# RK3399-AP register map
File version: 1
CPU: CA7 r0p1, little endian, MPU, FPU, I-cache, D-cache, VTOR, 4 interrupt priority bits, 0 interrupts
Registers are 32-bit, read-write, reset 0x0 unless marked. A register's access mark holds for its fields unless they carry their own. Offsets are from the block's base; [hi:lo] are bit positions.

## GMAC (part 2 of 2)
Base 0xFE300000
0x190 GMAC_MMC_RXMCFRMCNT_G — MMC RX Multicast Frame Good Counter/MMC RX Mulitcast Frame Good Counter
  [31:0] RXMULTICASTFRAMES_G — Number of good multicast frames received.
0x194 GMAC_MMC_RXCRCERR — MMC RX Carrier
  [31:0] RXCRCERROR — Number of frames received with CRC error.
0x1C8 GMAC_MMC_RXLENERR — MMC RX Length Error
  [31:0] RXLENGTHERROR — Number of frames received with length error (Length type field ≠frame size), for all frames with valid length field.
0x1D4 GMAC_MMC_RXFIFOOVRFLW — MMC RX FIFO Overflow
  [31:0] RXFIFOOVERFLOW — Number of missed received frames due to FIFO overflow.
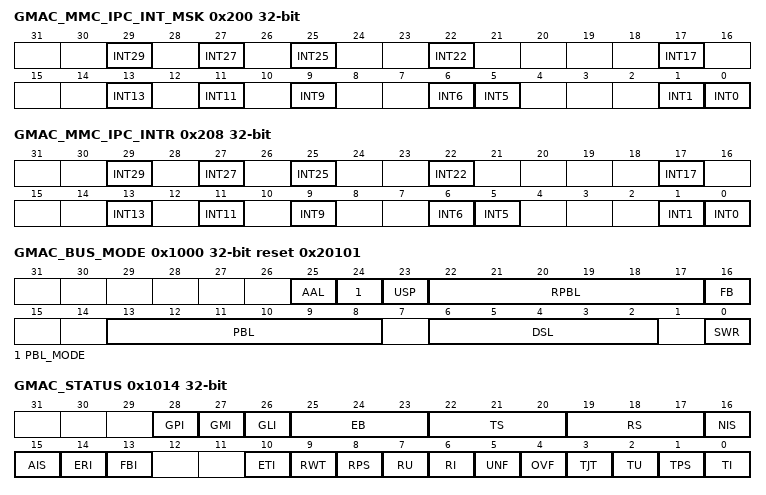
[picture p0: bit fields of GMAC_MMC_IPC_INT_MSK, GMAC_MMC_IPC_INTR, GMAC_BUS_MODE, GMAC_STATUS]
0x200 GMAC_MMC_IPC_INT_MSK — MMC Receive Checksum Offload Interrupt Mask Register
  [29] INT29 — Setting this bit masks the interrupt when the rxicmp_err_octets counter reaches half the maximum value, and also when it reaches the maximum value.
  [27] INT27 — Setting this bit masks the interrupt when the rxtcp_err_octets counter reaches half the maximum value, and also when it reaches the maximum value.
  [25] INT25 — Setting this bit masks the interrupt when the rxudp_err_octets counter reaches half the maximum value, and also when it reaches the maximum value.
  [22] INT22 — Setting this bit masks the interrupt when the rxipv6_hdrerr_octets counter reaches half the maximum value, and also when it reaches the maximum value.
  [17] INT17 — Setting this bit masks the interrupt when the rxipv4_hdrerr_octets counter reaches half the maximum value, and also when it reaches the maximum value.
  [13] INT13 — Setting this bit masks the interrupt when the rxicmp_err_frms counter reaches half the maximum value, and also when it reaches the maximum value.
  [11] INT11 — Setting this bit masks the interrupt when the rxtcp_err_frms counter reaches half the maximum value, and also when it reaches the maximum value.
  [9] INT9 — Setting this bit masks the interrupt when the rxudp_err_frms counter reaches half the maximum value, and also when it reaches the maximum value.
  [6] INT6 — Setting this bit masks the interrupt when the rxipv6_hdrerr_frms counter reaches half the maximum value, and also when it reaches the maximum value.
  [5] INT5 — Setting this bit masks the interrupt when the rxipv6_gd_frms counter reaches half the maximum value, and also when it reaches the maximum value.
  [1] INT1 — Setting this bit masks the interrupt when the rxipv4_hdrerr_frms counter reaches half the maximum value, and also when it reaches the maximum value.
  [0] INT0 — Setting this bit masks the interrupt when the rxipv4_gd_frms counter reaches half the maximum value, and also when it reaches the maximum value.
0x208 GMAC_MMC_IPC_INTR ro — MMC Receive Checksum Offload Interrupt Register
  [29] INT29 read-clears — The bit is set when the rxicmp_err_octets counter reaches half the maximum value, and also when it reaches the maximum value.
  [27] INT27 read-clears — The bit is set when the rxtcp_err_octets counter reaches half the maximum value, and also when it reaches the maximum value.
  [25] INT25 read-clears — The bit is set when the rxudp_err_octets counter reaches half the maximum value, and also when it reaches the maximum value.
  [22] INT22 read-clears — The bit is set when the rxipv6_hdrerr_octets counter reaches half the maximum value, and also when it reaches the maximum value.
  [17] INT17 read-clears — The bit is set when the rxipv4_hdrerr_octets counter reaches half the maximum value, and also when it reaches the maximum value.
  [13] INT13 read-clears — The bit is set when the rxicmp_err_frms counter reaches half the maximum value, and also when it reaches the maximum value.
  [11] INT11 read-clears — The bit is set when the rxtcp_err_frms counter reaches half the maximum value, and also when it reaches the maximum value.
  [9] INT9 read-clears — The bit is set when the rxudp_err_frms counter reaches half the maximum value, and also when it reaches the maximum value.
  [6] INT6 read-clears — The bit is set when the rxipv6_hdrerr_frms counter reaches half the maximum value, and also when it reaches the maximum value.
  [5] INT5 read-clears — The bit is set when the rxipv6_gd_frms counter reaches half the maximum value, and also when it reaches the maximum value.
  [1] INT1 read-clears — The bit is set when the rxipv4_hdrerr_frms counter reaches half the maximum value, and also when it reaches the maximum value.
  [0] INT0 read-clears — The bit is set when the rxipv4_gd_frms counter reaches half the maximum value, and also when it reaches the maximum value.
0x210 GMAC_MMC_RXIPV4GFRM — MMC RX IPV4 Good Frame
  [31:0] RXIPV4_GD_FRMS — Number of good IPv4 datagrams received with the TCP, UDP, or ICMP payload
0x214 GMAC_MMC_RXIPV4HDERRFRM — MMC RX IPV4 Head Error Frame
  [31:0] RXIPV4_HDRERR_FRMS — Number of IPv4 datagrams received with header (checksum, length, or version mismatch) errors
0x224 GMAC_MMC_RXIPV6GFRM — MMC RX IPV6 Good Frame
  [31:0] RXIPV6_GD_FRMS — Number of good IPv6 datagrams received with TCP, UDP, or ICMP payloads.
0x228 GMAC_MMC_RXIPV6HDERRFRM — MMC RX IPV6 Head Error Frame
  [31:0] RXIPV6_HDRERR_FRMS — Number of IPv6 datagrams received with header errors (length or version mismatch).
0x234 GMAC_MMC_RXUDPERRFRM — MMC RX UDP Error Frame
  [31:0] RXUDP_ERR_FRMS — Number of good IP datagrams whose UDP payload has a checksum error.
0x23C GMAC_MMC_RXTCPERRFRM — MMC RX TCP Error Frame
  [31:0] RXTCP_ERR_FRMS — Number of good IP datagrams whose TCP payload has a checksum error.
0x244 GMAC_MMC_RXICMPERRFRM — MMC RX ICMP Error Frame
  [31:0] RXICMP_ERR_FRMS — Number of good IP datagrams whose ICMP payload has a checksum error.
0x254 GMAC_MMC_RXIPV4HDERROCT — MMC RX OCTET IPV4 Head Error
  [31:0] RXIPV4_HDRERR_OCTETS — Number of bytes received in IPv4 datagrams with header errors (checksum, length, version mismatch). The value in the Length field of IPv4 header is used to update this counter.
0x268 GMAC_MMC_RXIPV6HDERROCT — MMC RX OCTET IPV6 Head Error
  [31:0] RXIPV6_HDRERR_OCTETS — Number of bytes received in IPv6 datagrams with header errors (length, version mismatch). The value in the IPv6 header\'s Length field is used to update this counter.
0x274 GMAC_MMC_RXUDPERROCT — MMC RX OCTET UDP Error
  [31:0] RXUDP_ERR_OCTETS — Number of bytes received in a UDP segment that had checksum errors.
0x27C GMAC_MMC_RXTCPERROCT — MMC RX OCTET TCP Error
  [31:0] RXTCP_ERR_OCTETS — Number of bytes received in a TCP segment with checksum errors.
0x284 GMAC_MMC_RXICMPERROCT — MMC RX OCTET ICMP Error
  [31:0] RXICMP_ERR_OCTETS — Number of bytes received in an ICMP segment with checksum errors.
0x1000 GMAC_BUS_MODE access per field reset 0x20101 — Bus Mode Register
  [25] AAL rw — Address-Aligned Beats When this bit is set high and the FB bit equals 1, the AXI interface generates all bursts aligned to the start address LS bits. If the FB bit equals 0, the first burst (accessing the data buffer\'s start address) is not aligned, but subsequent bursts are aligned to the address.
  [24] PBL_MODE rw — 8xPBL Mode When set high, this bit multiplies the PBL value programmed (bits [22:17] and bits [13:8]) eight times. Thus the DMA will transfer data in to a maximum of 8, 16, 32, 64, 128, and 256 beats depending on the PBL value.
  [23] USP rw — Use Separate PBL When set high, it configures the RxDMA to use the value configured in bits [22:17] as PBL while the PBL value in bits [13:8] is applicable to TxDMA operations only. When reset to low, the PBL value in bits [13:8] is applicable for both DMA engines.
  [22:17] RPBL rw — RxDMA PBL These bits indicate the maximum number of beats to be transferred in one RxDMA transaction. This will be the maximum value that is used in a single block Read/Write. The RxDMA will always attempt to burst as specified in RPBL each time it starts a Burst transfer on the host bus. RPBL can be programmed with permissible values of 1, 2, 4, 8, 16, and 32. Any other value will result in undefined behavior. These bits are valid and applicable only when USP is set high.
  [16] FB rw — Fixed Burst This bit controls whether the AXI Master interface performs fixed burst transfers or not. When set, the AHB will use only SINGLE, INCR4, INCR8 or INCR16 during start of normal burst transfers. When reset, the AXI will use SINGLE and INCR burst transfer operations.
  [13:8] PBL rw — Programmable Burst Length These bits indicate the maximum number of beats to be transferred in one DMA transaction. This will be the maximum value that is used in a single block Read/Write. The DMA will always attempt to burst as specified in PBL each time it starts a Burst transfer on the host bus. PBL can be programmed with permissible values of 1, 2, 4, 8, 16, and 32. Any other value will result in undefined behavior. When USP is set high, this PBL value is applicable for TxDMA transactions only. The PBL values have the following limitations. The maximum number of beats (PBL) possible is limited by the size of the Tx FIFO and Rx FIFO in the MTL layer and the data bus width on the DMA. The FIFO has a constraint that the maximum beat supported is half the depth of the FIFO, except when specified (as given below). For different data bus widths and FIFO sizes, the valid PBL range (including x8 mode) is provided in the following table. If the PBL is common for both transmit and receive DMA, the minimum Rx FIFO and Tx FIFO depths must be considered. Do not program out-of-range PBL values, because the system may not behave properly. For TxFIFO, valid PBL range in full duplex mode and duplex mode is 128 or less. For RxFIFO, valid PBL range in full duplex mode is all.
  [6:2] DSL rw — Descriptor Skip Length This bit specifies the number of dword to skip between two unchained descriptors. The address skipping starts from the end of current descriptor to the start of next descriptor. When DSL value equals zero, then the descriptor table is taken as contiguous by the DMA, in Ring mode.
  [0] SWR wo write-clears — Software Reset When this bit is set, the MAC DMA Controller resets all GMAC Subsystem internal registers and logic. It is cleared automatically after the reset operation has completed in all of the core clock domains. Read a 0 value in this bit before re-programming any register of the core. Note: The reset operation is completed only when all the resets in all the active clock domains are de-asserted. Hence it is essential that all the PHY inputs clocks (applicable for the selected PHY interface) are present for software reset completion.
0x1004 GMAC_TX_POLL_DEMAND ro — Transmit Poll Demand Register
  [31:0] TPD — Transmit Poll Demand When these bits are written with any value, the DMA reads the current descriptor pointed to by Register GMAC_CUR_HOST_TX_DESC. If that descriptor is not available (owned by Host), transmission returns to the Suspend state and DMA Register GMAC_STATUS[2] is asserted. If the descriptor is available, transmission resumes.
0x1008 GMAC_RX_POLL_DEMAND ro — Receive Poll Demand Register
  [31:0] RPD — Receive Poll Demand When these bits are written with any value, the DMA reads the current descriptor pointed to by Register GMAC_CUR_HOST_RX_DESC. If that descriptor is not available (owned by Host), reception returns to the Suspended state and Register GMAC_STATUS[7] is not asserted. If the descriptor is available, the Receive DMA returns to active state.
0x100C GMAC_RX_DESC_LIST_ADDR — Receive Descriptor List Address Register
  [31:0] SRL — Start of Receive List This field contains the base address of the First Descriptor in the Receive Descriptor list. The LSB bits [1/2/3:0] for 32/64/128-bit bus width) will be ignored and taken as all-zero by the DMA internally. Hence these LSB bits are Read Only.
0x1010 GMAC_TX_DESC_LIST_ADDR — Transmit Descriptor List Address Register
  [31:0] STL — Start of Transmit List This field contains the base address of the First Descriptor in the Transmit Descriptor list. The LSB bits [1/2/3:0] for 32/64/128-bit bus width) will be ignored and taken as all-zero by the DMA internally. Hence these LSB bits are Read Only.
0x1014 GMAC_STATUS access per field — Status Register
  [28] GPI ro — GMAC PMT Interrupt This bit indicates an interrupt event in the GMAC core\'s PMT module. The software must read the corresponding registers in the GMAC core to get the exact cause of interrupt and clear its source to reset this bit to 1\'b0. The interrupt signal from the GMAC subsystem (sbd_intr_o) is high when this bit is high.
  [27] GMI ro — GMAC MMC Interrupt This bit reflects an interrupt event in the MMC module of the GMAC core. The software must read the corresponding registers in the GMAC core to get the exact cause of interrupt and clear the source of interrupt to make this bit as 1\'b0. The interrupt signal from the GMAC subsystem (sbd_intr_o) is high when this bit is high.
  [26] GLI ro — GMAC Line interface Interrupt This bit reflects an interrupt event in the GMAC Core\'s PCS or RGMII interface block. The software must read the corresponding registers in the GMAC core to get the exact cause of interrupt and clear the source of interrupt to make this bit as 1\'b0. The interrupt signal from the GMAC subsystem (sbd_intr_o) is high when this bit is high.
  [25:23] EB ro — Error Bits These bits indicate the type of error that caused a Bus Error (e.g., error response on the AXI interface). Valid only with Fatal Bus Error bit (Register GMAC_STATUS[13]) set. This field does not generate an interrupt. Bit 23: 1\'b1 Error during data transfer by TxDMA 1\'b0 Error during data transfer by RxDMA Bit 24: 1\'b1 Error during read transfer 1\'b0 Error during write transfer Bit 25: 1\'b1 Error during descriptor access 1\'b0 Error during data buffer access
  [22:20] TS ro — Transmit Process State These bits indicate the Transmit DMA FSM state. This field does not generate an interrupt. 3\'b000: Stopped; Reset or Stop Transmit Command issued. 3\'b001: Running; Fetching Transmit Transfer Descriptor. 3\'b010: Running; Waiting for status. 3\'b011: Running; Reading Data from host memory buffer and queuing it to transmit buffer (Tx FIFO). 3\'b100: TIME_STAMP write state. 3\'b101: Reserved for future use. 3\'b110: Suspended; Transmit Descriptor Unavailable or Transmit Buffer Underflow. 3\'b111: Running; Closing Transmit Descriptor.
  [19:17] RS ro — Receive Process State These bits indicate the Receive DMA FSM state. This field does not generate an interrupt. 3\'b000: Stopped: Reset or Stop Receive Command issued. 3\'b001: Running: Fetching Receive Transfer Descriptor. 3\'b010: Reserved for future use. 3\'b011: Running: Waiting for receive packet. 3\'b100: Suspended: Receive Descriptor Unavailable. 3\'b101: Running: Closing Receive Descriptor. 3\'b110: TIME_STAMP write state. 3\'b111: Running: Transferring the receive packet data from receive buffer to host memory.
  [16] NIS rw write-1-clears — Normal Interrupt Summary Normal Interrupt Summary bit value is the logical OR of the following when the corresponding interrupt bits are enabled in Register OP_MODE: Register GMAC_STATUS[0]: Transmit Interrupt Register GMAC_STATUS[2]: Transmit Buffer Unavailable Register GMAC_STATUS[6]: Receive Interrupt Register GMAC_STATUS[14]: Early Receive Interrupt Only unmasked bits affect the Normal Interrupt Summary bit. This is a sticky bit and must be cleared (by writing a 1 to this bit) each time a corresponding bit that causes NIS to be set is cleared.
  [15] AIS rw write-1-clears — Abnormal Interrupt Summary Abnormal Interrupt Summary bit value is the logical OR of the following when the corresponding interrupt bits are enabled in Register OP_MODE: Register GMAC_STATUS[1]: Transmit Process Stopped Register GMAC_STATUS[3]: Transmit Jabber Timeout Register GMAC_STATUS[4]: Receive FIFO Overflow Register GMAC_STATUS[5]: Transmit Underflow Register GMAC_STATUS[7]: Receive Buffer Unavailable Register GMAC_STATUS[8]: Receive Process Stopped Register GMAC_STATUS[9]: Receive Watchdog Timeout Register GMAC_STATUS[10]: Early Transmit Interrupt Register GMAC_STATUS[13]: Fatal Bus Error Only unmasked bits affect the Abnormal Interrupt Summary bit. This is a sticky bit and must be cleared each time a corresponding bit that causes AIS to be set is cleared.
  [14] ERI rw write-1-clears — Early Receive Interrupt This bit indicates that the DMA had filled the first data buffer of the packet. Receive Interrupt Register GMAC_STATUS[6] automatically clears this bit.
  [13] FBI rw write-1-clears — Fatal Bus Error Interrupt This bit indicates that a bus error occurred, as detailed in [25:23]. When this bit is set, the corresponding DMA engine disables all its bus accesses.
  [10] ETI rw write-1-clears — Early Transmit Interrupt This bit indicates that the frame to be transmitted was fully transferred to the MTL Transmit FIFO.
  [9] RWT rw write-1-clears — Receive Watchdog Timeout This bit is asserted when a frame with a length greater than 2,048 bytes is received.
  [8] RPS rw write-1-clears — Receive Process Stopped This bit is asserted when the Receive Process enters the Stopped state.
  [7] RU rw write-1-clears — Receive Buffer Unavailable This bit indicates that the Next Descriptor in the Receive List is owned by the host and cannot be acquired by the DMA. Receive Process is suspended. To resume processing Receive descriptors, the host should change the ownership of the descriptor and issue a Receive Poll Demand command. If no Receive Poll Demand is issued, Receive Process resumes when the next recognized incoming frame is received. Register GMAC_STATUS[7] is set only when the previous Receive Descriptor was owned by the DMA.
  [6] RI rw write-1-clears — Receive Interrupt This bit indicates the completion of frame reception. Specific frame status information has been posted in the descriptor. Reception remains in the Running state.
  [5] UNF rw write-1-clears — Transmit Underflow This bit indicates that the Transmit Buffer had an Underflow during frame transmission. Transmission is suspended and an Underflow Error TDES0[1] is set.
  [4] OVF rw write-1-clears — Receive Overflow This bit indicates that the Receive Buffer had an Overflow during frame reception. If the partial frame is transferred to application, the overflow status is set in RDES0[11].
  [3] TJT rw write-1-clears — Transmit Jabber Timeout This bit indicates that the Transmit Jabber Timer expired, meaning that the transmitter had been excessively active. The transmission process is aborted and placed in the Stopped state. This causes the Transmit Jabber Timeout TDES0[14] flag to assert.
  [2] TU rw write-1-clears — Transmit Buffer Unavailable This bit indicates that the Next Descriptor in the Transmit List is owned by the host and cannot be acquired by the DMA. Transmission is suspended. Bits[22:20] explain the Transmit Process state transitions. To resume processing transmit descriptors, the host should change the ownership of the bit of the descriptor and then issue a Transmit Poll Demand command.
  [1] TPS rw write-1-clears — Transmit Process Stopped This bit is set when the transmission is stopped.
  [0] TI rw write-1-clears — Transmit Interrupt This bit indicates that frame transmission is finished and TDES1[31] is set in the First Descriptor.
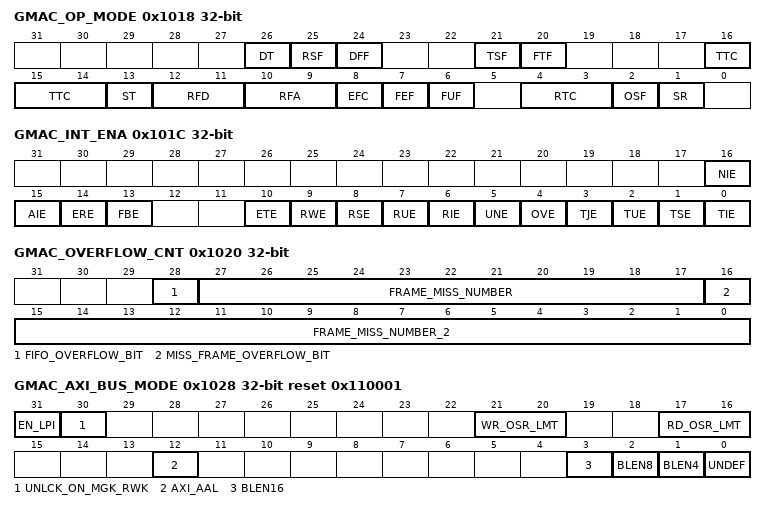
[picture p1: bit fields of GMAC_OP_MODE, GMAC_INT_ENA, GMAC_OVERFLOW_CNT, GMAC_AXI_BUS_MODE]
0x1018 GMAC_OP_MODE — Operation Mode Register
  [26] DT — Disable Dropping of TCP/IP Checksum Error Frames When this bit is set, the core does not drop frames that only have errors detected by the Receive Checksum Offload engine. Such frames do not have any errors (including FCS error) in the Ethernet frame received by the MAC but have errors in the encapsulated payload only. When this bit is reset, all error frames are dropped if the FEF bit is reset.
  [25] RSF — Receive Store and Forward When this bit is set, the MTL only reads a frame from the Rx FIFO after the complete frame has been written to it, ignoring RTC bits. When this bit is reset, the Rx FIFO operates in Cut-Through mode, subject to the threshold specified by the RTC bits.
  [24] DFF — Disable Flushing of Received Frames When this bit is set, the RxDMA does not flush any frames due to the unavailability of receive descriptors/buffers as it does normally when this bit is reset.
  [21] TSF — Transmit Store and Forward When this bit is set, transmission starts when a full frame resides in the MTL Transmit FIFO. When this bit is set, the TTC values specified in Register GMAC_OP_MODE[16:14] are ignored. This bit should be changed only when transmission is stopped.
  [20] FTF write-1-clears — Flush Transmit FIFO When this bit is set, the transmit FIFO controller logic is reset to its default values and thus all data in the Tx FIFO is lost/flushed. This bit is cleared internally when the flushing operation is completed fully. The Operation Mode register should not be written to until this bit is cleared. The data which is already accepted by the MAC transmitter will not be flushed. It will be scheduled for transmission and will result in underflow and runt frame transmission. Note: The flush operation completes only after emptying the TxFIFO of its contents and all the pending Transmit Status of the transmitted frames are accepted by the host. In order to complete this flush operation, the PHY transmit clock (clk_tx_i) is required to be active.
  [16:14] TTC — Transmit Threshold Control These three bits control the threshold level of the MTL Transmit FIFO. Transmission starts when the frame size within the MTL Transmit FIFO is larger than the threshold. In addition, full frames with a length less than the threshold are also transmitted. These bits are used only when the TSF bit (Bit 21) is reset. 3\'b000: 64 3\'b001: 128 3\'b010: 192 3\'b011: 256 3\'b100: 40 3\'b101: 32 3\'b110: 24 3\'b111: 16
  [13] ST — Start/Stop Transmission Command When this bit is set, transmission is placed in the Running state, and the DMA checks the Transmit List at the current position for a frame to be transmitted. Descriptor acquisition is attempted either from the current position in the list, which is the Transmit List Base Address set by Register GMAC_TX_DESC_LIST_ADDR, or from the position retained when transmission was stopped previously. If the current descriptor is not owned by the DMA, transmission enters the Suspended state and Transmit Buffer Unavailable (Register GMAC_STATUS[2]) is set. The Start Transmission command is effective only when transmission is stopped. If the command is issued before setting DMA Register TX_DESC_LIST_ADDR, then the DMA behavior is unpredictable. When this bit is reset, the transmission process is placed in the Stopped state after completing the transmission of the current frame. The Next Descriptor position in the Transmit List is saved, and becomes the current position when transmission is restarted. The stop transmission command is effective only the transmission of the current frame is complete or when the transmission is in the Suspended state.
  [12:11] RFD — Threshold for deactivating flow control (in both HD and FD) These bits control the threshold (Fill-level of Rx FIFO) at which the flow-control is de-asserted after activation. 2\'b00: Full minus 1 KB 2\'b01: Full minus 2 KB 2\'b10: Full minus 3 KB 2\'b11: Full minus 4 KB Note that the de-assertion is effective only after flow control is asserted.
  [10:9] RFA — Threshold for activating flow control (in both HD and FD) These bits control the threshold (Fill level of Rx FIFO) at which flow control is activated. 2\'b00: Full minus 1 KB 2\'b01: Full minus 2 KB 2\'b10: Full minus 3 KB 2\'b11: Full minus 4 KB Note that the above only applies to Rx FIFOs of 4 KB or more when the EFC bit is set high.
  [8] EFC — Enable HW flow control When this bit is set, the flow control signal operation based on fill-level of Rx FIFO is enabled. When reset, the flow control operation is disabled.
  [7] FEF — Forward Error Frames When this bit is reset, the Rx FIFO drops frames with error status (CRC error, collision error, GMII_ER, giant frame, watchdog timeout, overflow). However, if the frame\'s start byte (write) pointer is already transferred to the read controller side (in Threshold mode), then the frames are not dropped. When FEF is set, all frames except runt error frames are forwarded to the DMA. But when RxFIFO overflows when a partial frame is written, then such frames are dropped even when FEF is set.
  [6] FUF — Forward Undersized Good Frames When set, the Rx FIFO will forward Undersized frames (frames with no Error and length less than 64 bytes) including pad-bytes and CRC). When reset, the Rx FIFO will drop all frames of less than 64 bytes, unless it is already transferred due to lower value of Receive Threshold (e.g., RTC = 01).
  [4:3] RTC — Receive Threshold Control These two bits control the threshold level of the MTL Receive FIFO. Transfer (request) to DMA starts when the frame size within the MTL Receive FIFO is larger than the threshold. In addition, full frames with a length less than the threshold are transferred automatically. Note that value of 11 is not applicable if the configured Receive FIFO size is 128 bytes. These bits are valid only when the RSF bit is zero, and are ignored when the RSF bit is set to 1. 2\'b00: 64 2\'b01: 32 2\'b10: 96 2\'b11: 128
  [2] OSF — Operate on Second Frame When this bit is set, this bit instructs the DMA to process a second frame of Transmit data even before status for first frame is obtained.
  [1] SR — Start/Stop Receive When this bit is set, the Receive process is placed in the Running state. The DMA attempts to acquire the descriptor from the Receive list and processes incoming frames. Descriptor acquisition is attempted from the current position in the list, which is the address set by register GMAC_RX_DESC_LIST_ADDR or the position retained when the Receive process was previously stopped. If no descriptor is owned by the DMA, reception is suspended and Receive Buffer Unavailable (Register GMAC_STATUS[7]) is set. The Start Receive command is effective only when reception has stopped. If the command was issued before setting register GMAC_RX_DESC_LIST_ADDR, DMA behavior is unpredictable. When this bit is cleared, RxDMA operation is stopped after the transfer of the current frame. The next descriptor position in the Receive list is saved and becomes the current position after the Receive process is restarted. The Stop Receive command is effective only when the Receive process is in either the Running (waiting for receive packet) or in the Suspended state.
0x101C GMAC_INT_ENA — Interrupt Enable Register
  [16] NIE — Normal Interrupt Summary Enable When this bit is set, a normal interrupt is enabled. When this bit is reset, a normal interrupt is disabled. This bit enables the following bits: Register GMAC_STATUS[0]: Transmit Interrupt Register GMAC_STATUS[2]: Transmit Buffer Unavailable Register GMAC_STATUS[6]: Receive Interrupt Register GMAC_STATUS[14]: Early Receive Interrupt
  [15] AIE — Abnormal Interrupt Summary Enable When this bit is set, an Abnormal Interrupt is enabled. When this bit is reset, an Abnormal Interrupt is disabled. This bit enables the following bits Register GMAC_STATUS[1]: Transmit Process Stopped Register GMAC_STATUS[3]: Transmit Jabber Timeout Register GMAC_STATUS[4]: Receive Overflow Register GMAC_STATUS[5]: Transmit Underflow Register GMAC_STATUS[7]: Receive Buffer Unavailable Register GMAC_STATUS[8]: Receive Process Stopped Register GMAC_STATUS[9]: Receive Watchdog Timeout Register GMAC_STATUS[10]: Early Transmit Interrupt Register GMAC_STATUS[13]: Fatal Bus Error
  [14] ERE — Early Receive Interrupt Enable When this bit is set with Normal Interrupt Summary Enable (BIT 16), Early Receive Interrupt is enabled. When this bit is reset, Early Receive Interrupt is disabled.
  [13] FBE — Fatal Bus Error Enable When this bit is set with Abnormal Interrupt Summary Enable (BIT 15), the Fatal Bus Error Interrupt is enabled. When this bit is reset, Fatal Bus Error Enable Interrupt is disabled.
  [10] ETE — Early Transmit Interrupt Enable When this bit is set with an Abnormal Interrupt Summary Enable (BIT 15), Early Transmit Interrupt is enabled. When this bit is reset, Early Transmit Interrupt is disabled.
  [9] RWE — Receive Watchdog Timeout Enable When this bit is set with Abnormal Interrupt Summary Enable (BIT 15), the Receive Watchdog Timeout Interrupt is enabled. When this bit is reset, Receive Watchdog Timeout Interrupt is disabled.
  [8] RSE — Receive Stopped Enable When this bit is set with Abnormal Interrupt Summary Enable (BIT 15), Receive Stopped Interrupt is enabled. When this bit is reset, Receive Stopped Interrupt is disabled.
  [7] RUE — Receive Buffer Unavailable Enable When this bit is set with Abnormal Interrupt Summary Enable (BIT 15), Receive Buffer Unavailable Interrupt is enabled. When this bit is reset, the Receive Buffer Unavailable Interrupt is disabled
  [6] RIE — Receive Interrupt Enable When this bit is set with Normal Interrupt Summary Enable (BIT 16), Receive Interrupt is enabled. When this bit is reset, Receive Interrupt is disabled.
  [5] UNE — Underflow Interrupt Enable When this bit is set with Abnormal Interrupt Summary Enable (BIT 15), Transmit Underflow Interrupt is enabled. When this bit is reset, Underflow Interrupt is disabled.
  [4] OVE — Overflow Interrupt Enable When this bit is set with Abnormal Interrupt Summary Enable (BIT 15), Receive Overflow Interrupt is enabled. When this bit is reset, Overflow Interrupt is disabled
  [3] TJE — Transmit Jabber Timeout Enable When this bit is set with Abnormal Interrupt Summary Enable (BIT 15), Transmit Jabber Timeout Interrupt is enabled. When this bit is reset, Transmit Jabber Timeout Interrupt is disabled.
  [2] TUE — Transmit Buffer Unavailable Enable When this bit is set with Normal Interrupt Summary Enable (BIT 16), Transmit Buffer Unavailable Interrupt is enabled. When this bit is reset, Transmit Buffer Unavailable Interrupt is disabled.
  [1] TSE — Transmit Stopped Enable When this bit is set with Abnormal Interrupt Summary Enable (BIT 15), Transmission Stopped Interrupt is enabled. When this bit is reset, Transmission Stopped Interrupt is disabled.
  [0] TIE — Transmit Interrupt Enable When this bit is set with Normal Interrupt Summary Enable (BIT 16), Transmit Interrupt is enabled. When this bit is reset, Transmit Interrupt is disabled.
0x1020 GMAC_OVERFLOW_CNT ro — Missed Frame and Buffer Overflow Counter Register
  [28] FIFO_OVERFLOW_BIT read-clears — Overflow bit for FIFO Overflow Counter
  [27:17] FRAME_MISS_NUMBER read-clears — Indicates the number of frames missed by the application This counter is incremented each time the MTL asserts the sideband signal mtl_rxoverflow_o. The counter is cleared when this register is read with mci_be_i[2] at 1\'b1.
  [16] MISS_FRAME_OVERFLOW_BIT read-clears — Overflow bit for Missed Frame Counter
  [15:0] FRAME_MISS_NUMBER_2 read-clears — Indicates the number of frames missed by the controller due to the Host Receive Buffer being unavailable. This counter is incremented each time the DMA discards an incoming frame. The counter is cleared when this register is read with mci_be_i[0] at 1\'b1.
0x1024 GMAC_REC_INT_WDT_TIMER — Receive Interrupt Watchdog Timer Register
  [7:0] RIWT — RI Watchdog Timer count Indicates the number of system clock cycles multiplied by 256 for which the watchdog timer is set. The watchdog timer gets triggered with the programmed value after the RxDMA completes the transfer of a frame for which the RI status bit is not set due to the setting in the corresponding descriptor RDES1[31]. When the watch-dog timer runs out, the RI bit is set and the timer is stopped. The watchdog timer is reset when RI bit is set high due to automatic setting of RI as per RDES1[31] of any received frame.
0x1028 GMAC_AXI_BUS_MODE access per field reset 0x110001 — AXI Bus Mode Register
  [31] EN_LPI rw — Enable LPI (Low Power Interface) When set to 1, enable the LPI (Low Power Interface) supported by the GMAC and accepts the LPI request from the AXI System Clock controller. When set to 0, disables the Low Power Mode and always denies the LPI request from the AXI System Clock controller.
  [30] UNLCK_ON_MGK_RWK rw — Unlock on Magic Packet or Remote Wake Up When set to 1, enables it to request coming out of Low Power mode only when Magic Packet or Remote Wake Up Packet is received. When set to 0, enables it requests to come out of Low Power mode when any frame is received.
  [21:20] WR_OSR_LMT rw — AXI Maximum Write Out Standing Request Limit This value limits the maximum outstanding request on the AXI write interface. Maximum outstanding requests = WR_OSR_LMT+1
  [17:16] RD_OSR_LMT rw — AXI Maximum Read Out Standing Request Limit This value limits the maximum outstanding request on the AXI read interface. Maximum outstanding requests = RD_OSR_LMT+1
  [12] AXI_AAL ro — Address-Aligned Beats This bit is read-only bit and reflects the AAL bit (register GMAC_BUS_MODE[25]). When this bit set to 1, it performs address-aligned burst transfers on both read and write channels.
  [3] BLEN16 rw — AXI Burst Length 16 When this bit is set to 1, or when UNDEF is set to 1, it is allowed to select a burst length of 16.
  [2] BLEN8 rw — AXI Burst Length 8 When this bit is set to 1, or when UNDEF is set to 1, it is allowed to select a burst length of 8.
  [1] BLEN4 rw — AXI Burst Length 4 When this bit is set to 1, or when UNDEF is set to 1, it is allowed to select a burst length of 4.
  [0] UNDEF ro — AXI Undefined Burst Length This bit is read-only bit and indicates the complement (invert) value of FB bit in register GMAC_BUS_MODE[16]. When this bit is set to 1, it is allowed to perform any burst length equal to or below the maximum allowed burst length as programmed in bits[7:1]; When this bit is set to 0, it is allowed to perform only fixed burst lengths as indicated by BLEN256/128/64/32/16/8/4, or a burst length of 1.
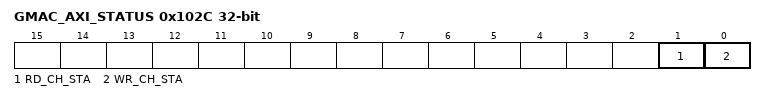
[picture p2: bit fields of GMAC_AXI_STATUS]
0x102C GMAC_AXI_STATUS ro — AXI Status Register
  [1] RD_CH_STA — When high, it indicates that AXI Master\'s read channel is active and transferring data.
  [0] WR_CH_STA — When high, it indicates that AXI Master\'s write channel is active and transferring data.
0x1048 GMAC_CUR_HOST_TX_DESC ro — Current Host Transmit Descriptor Register
  [31:0] HTDAP — Host Transmit Descriptor Address Pointer Cleared on Reset. Pointer updated by DMA during operation.
0x104C GMAC_CUR_HOST_RX_DESC ro — Current Host Receive Descriptor Register
  [31:0] HRDAP — Host Receive Descriptor Address Pointer Cleared on Reset. Pointer updated by DMA during operation. HTBAP Host Transmit Buffer Address Pointer Cleared on Reset. Pointer updated by DMA during operation.
0x1050 GMAC_CUR_HOST_TX_BUF_ADDR access not given — Current Host Transmit Buffer Address Register
0x1054 GMAC_CUR_HOST_RX_BUF_ADDR ro — Current Host Receive Buffer Address Register/Current Host Receive Buffer Adderss Register
  [31:0] HRBAP — Host Receive Buffer Address Pointer Cleared on Reset. Pointer updated by DMA during operation.
